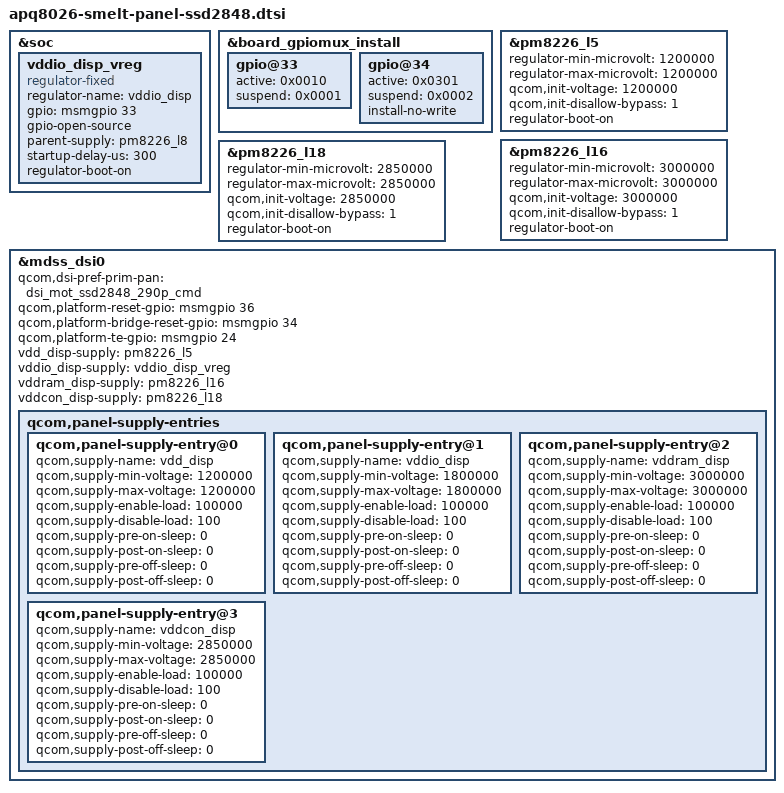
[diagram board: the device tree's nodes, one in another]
/* Copyright (c) 2014, The Linux Foundation. All rights reserved.
 *
 * This program is free software; you can redistribute it and/or modify
 * it under the terms of the GNU General Public License version 2 and
 * only version 2 as published by the Free Software Foundation.
 *
 * This program is distributed in the hope that it will be useful,
 * but WITHOUT ANY WARRANTY; without even the implied warranty of
 * MERCHANTABILITY or FITNESS FOR A PARTICULAR PURPOSE.  See the
 * GNU General Public License for more details.
 */

#include "qcom/dsi-panel-mot-ssd2848-290p-cmd.dtsi"

&soc {
	vddio_disp_vreg: vddio_disp_vreg {
		compatible = "regulator-fixed";
		regulator-name = "vddio_disp";
		gpio = <&msmgpio 33 0x0>;
		gpio-open-source;
		parent-supply = <&pm8226_l8>;
		startup-delay-us = <300>;
		regulator-boot-on;
	};
};

&board_gpiomux_install {
	gpio@33 {
		active  = <0x0010>; /* FUNC_GPIO, DRV_2MA, PULL_DOWN, IN */
		suspend = <0x0001>; /* FUNC_GPIO, DRV_2MA, PULL_NONE, OUT_HIGH */
	};
	gpio@34 {
		active  = <0x0301>; /* FUNC_GPIO, DRV_8MA, PULL_NONE, OUT_HIGH */
		suspend = <0x0002>; /* FUNC_GPIO, DRV_2MA, PULL_NONE, OUT_LOW */
		install-no-write;
	};
};

&pm8226_l5 {
	regulator-min-microvolt = <1200000>;
	regulator-max-microvolt = <1200000>;
	qcom,init-voltage = <1200000>;
	qcom,init-disallow-bypass = <1>;
	regulator-boot-on;
};

&pm8226_l16 {
	regulator-min-microvolt = <3000000>;
	regulator-max-microvolt = <3000000>;
	qcom,init-voltage = <3000000>;
	qcom,init-disallow-bypass = <1>;
	regulator-boot-on;
};

&pm8226_l18 {
	regulator-min-microvolt = <2850000>;
	regulator-max-microvolt = <2850000>;
	qcom,init-voltage = <2850000>;
	qcom,init-disallow-bypass = <1>;
	regulator-boot-on;
};


&mdss_dsi0 {
	qcom,dsi-pref-prim-pan = <&dsi_mot_ssd2848_290p_cmd>;
	qcom,platform-reset-gpio = <&msmgpio 36 0>;
	qcom,platform-bridge-reset-gpio = <&msmgpio 34 0>;
	qcom,platform-te-gpio = <&msmgpio 24 0>;
	vdd_disp-supply = <&pm8226_l5>;
	vddio_disp-supply = <&vddio_disp_vreg>;
	vddram_disp-supply = <&pm8226_l16>;
	vddcon_disp-supply = <&pm8226_l18>;
	qcom,panel-supply-entries {
		qcom,panel-supply-entry@0 {
			qcom,supply-name = "vdd_disp";
			qcom,supply-min-voltage = <1200000>;
			qcom,supply-max-voltage = <1200000>;
			qcom,supply-enable-load = <100000>;
			qcom,supply-disable-load = <100>;
			qcom,supply-pre-on-sleep = <0>;
			qcom,supply-post-on-sleep = <0>;
			qcom,supply-pre-off-sleep = <0>;
			qcom,supply-post-off-sleep = <0>;
		};
		qcom,panel-supply-entry@1 {
			qcom,supply-name = "vddio_disp";
			qcom,supply-min-voltage = <1800000>;
			qcom,supply-max-voltage = <1800000>;
			qcom,supply-enable-load = <100000>;
			qcom,supply-disable-load = <100>;
			qcom,supply-pre-on-sleep = <0>;
			qcom,supply-post-on-sleep = <0>;
			qcom,supply-pre-off-sleep = <0>;
			qcom,supply-post-off-sleep = <0>;
		};
		qcom,panel-supply-entry@2 {
			qcom,supply-name = "vddram_disp";
			qcom,supply-min-voltage = <3000000>;
			qcom,supply-max-voltage = <3000000>;
			qcom,supply-enable-load = <100000>;
			qcom,supply-disable-load = <100>;
			qcom,supply-pre-on-sleep = <0>;
			qcom,supply-post-on-sleep = <0>;
			qcom,supply-pre-off-sleep = <0>;
			qcom,supply-post-off-sleep = <0>;
		};
		qcom,panel-supply-entry@3 {
			qcom,supply-name = "vddcon_disp";
			qcom,supply-min-voltage = <2850000>;
			qcom,supply-max-voltage = <2850000>;
			qcom,supply-enable-load = <100000>;
			qcom,supply-disable-load = <100>;
			qcom,supply-pre-on-sleep = <0>;
			qcom,supply-post-on-sleep = <0>;
			qcom,supply-pre-off-sleep = <0>;
			qcom,supply-post-off-sleep = <0>;
		};
	};
};
